# ior7f701057 register map
Registers are 8-bit, access not given, no defined reset value unless marked. A register's access mark holds for its fields unless they carry their own. Addresses are absolute; registers are grouped by the start of their names; [hi:lo] are bit positions; {n}, {i} and the like mark numbered series.

## SFR (part 1 of 3)
0xFFA00000 FLMDCNT 32-bit
0xFFA00004 FLMDPCMD 32-bit wo
0xFFA00008 FLMDPS 32-bit ro
{0xFFA08000+4i} SELFID{i} 32-bit (i=0..3)
0xFFA08010 SELFIDST 32-bit ro
0xFFA10000 FACIFPMON ro
0xFFA10010 FACIFASTAT
0xFFA10014 FACIFAEINT
0xFFA10020 FACIFAREASELC 16-bit
0xFFA10030 FACIFSADDR 32-bit
0xFFA10034 FACIFEADDR 32-bit
0xFFA10054 FACIFCURAME 16-bit
0xFFA10080 FACIFSTATR 32-bit ro
0xFFA10084 FACIFENTRYR 16-bit
0xFFA10088 FACIFPROTR 16-bit
0xFFA1008C FACIFSUINITR 16-bit
0xFFA10090 FACIFLKSTAT ro
0xFFA10094 FACIFRFSTEADR 32-bit ro
0xFFA10098 FACIFRTSTAT ro
0xFFA100A0 FACIFCMDR 16-bit ro
0xFFA100C0 FACIFPESTAT 16-bit ro
0xFFA100D0 FACIFBCCNT
0xFFA100D4 FACIFBCSTAT ro
0xFFA100D8 FACIFPSADDR 32-bit ro
0xFFA100E0 FACIFCPSR 16-bit
0xFFA100E4 FACIFPCKAR 16-bit
0xFFA10100 FACIFECCEMON 16-bit ro
0xFFA10104 FACIFECCTMD 16-bit
0xFFA10108 FACIFDMYECC 16-bit
0xFFBC0700 PFSSBWCBUFEN
{0xFFBC1000+4i} SLPWGA{i} 32-bit (i=0..2)
0xFFBC2000 SCTLR 32-bit
0xFFBC2004 EVFR 32-bit
0xFFBC2008 DPSELR0 32-bit
0xFFBC200C DPSELRM 32-bit
0xFFBC200C DPSELRML 16-bit
{0xFFBC200B+i} DPSELR{i} (i=1..7)
0xFFBC200E DPSELRMH 16-bit
0xFFBC2010 DPSELRH 32-bit
0xFFBC2010 DPSELRHL 16-bit
0xFFBC2012 DPSELRHH 16-bit
0xFFBC2014 DPDSR0 32-bit
0xFFBC2018 DPDSRM 32-bit
0xFFBC2018 DPDSRML 16-bit
{0xFFBC2017+i} DPDSR{i} (i=1..7)
0xFFBC201A DPDSRMH 16-bit
0xFFBC201C DPDSRH 32-bit
0xFFBC201C DPDSRHL 16-bit
0xFFBC201E DPDSRHH 16-bit
0xFFBC2020 DPDIMR0 32-bit ro
{0xFFBC2020+4i} DPDIMR{i} ro (i=1..7)
0xFFBC2040 CNTVAL 16-bit
0xFFBC2044 SOSTR ro
{0xFFC10000+4i} P{i} 16-bit (i=0..2)
{0xFFC10000+4i} P{i} 16-bit (i=8..12)
0xFFC10048 P18 16-bit
0xFFC10050 P20 16-bit
0xFFC100C8 AP0 16-bit
0xFFC100CC AP1 16-bit
{0xFFC10100+4i} PSR{i} 32-bit (i=0..2)
{0xFFC10100+4i} PSR{i} 32-bit (i=8..12)
0xFFC10148 PSR18 32-bit
0xFFC10150 PSR20 32-bit
0xFFC101C8 APSR0 32-bit
0xFFC101CC APSR1 32-bit
{0xFFC10200+4i} PPR{i} 16-bit ro (i=0..2)
{0xFFC10200+4i} PPR{i} 16-bit ro (i=8..12)
0xFFC10248 PPR18 16-bit ro
0xFFC10250 PPR20 16-bit ro
0xFFC102C8 APPR0 16-bit ro
0xFFC102CC APPR1 16-bit ro
0xFFC102F0 IPPR0 16-bit ro
{0xFFC10300+4i} PM{i} 16-bit (i=0..2)
{0xFFC10300+4i} PM{i} 16-bit (i=8..12)
0xFFC10348 PM18 16-bit
0xFFC10350 PM20 16-bit
0xFFC103C8 APM0 16-bit
0xFFC103CC APM1 16-bit
{0xFFC10400+4i} PMC{i} 16-bit (i=0..2)
{0xFFC10400+4i} PMC{i} 16-bit (i=8..12)
0xFFC10448 PMC18 16-bit
0xFFC10450 PMC20 16-bit
0xFFC10500 PFC0 16-bit
0xFFC10504 PFC1 16-bit
{0xFFC10500+4i} PFC{i} 16-bit (i=8..12)
0xFFC10548 PFC18 16-bit
0xFFC10550 PFC20 16-bit
0xFFC10600 PFCE0 16-bit
{0xFFC10600+4i} PFCE{i} 16-bit (i=8..12)
{0xFFC10700+4i} PNOT{i} 16-bit wo (i=0..2)
{0xFFC10700+4i} PNOT{i} 16-bit wo (i=8..12)
0xFFC10748 PNOT18 16-bit wo
0xFFC10750 PNOT20 16-bit wo
0xFFC107C8 APNOT0 16-bit wo
0xFFC107CC APNOT1 16-bit wo
{0xFFC10800+4i} PMSR{i} 32-bit (i=0..2)
{0xFFC10800+4i} PMSR{i} 32-bit (i=8..12)
0xFFC10848 PMSR18 32-bit
0xFFC10850 PMSR20 32-bit
0xFFC108C8 APMSR0 32-bit
0xFFC108CC APMSR1 32-bit
{0xFFC10900+4i} PMCSR{i} 32-bit (i=0..2)
{0xFFC10900+4i} PMCSR{i} 32-bit (i=8..12)
0xFFC10948 PMCSR18 32-bit
0xFFC10950 PMCSR20 32-bit
0xFFC10A00 PFCAE0 16-bit
0xFFC10A28 PFCAE10 16-bit
0xFFC10A2C PFCAE11 16-bit
{0xFFC14000+4i} PIBC{i} 16-bit (i=0..2)
{0xFFC14000+4i} PIBC{i} 16-bit (i=8..12)
0xFFC14048 PIBC18 16-bit
0xFFC14050 PIBC20 16-bit
0xFFC140C8 APIBC0 16-bit
0xFFC140CC APIBC1 16-bit
0xFFC140F0 IPIBC0 16-bit
{0xFFC14100+4i} PBDC{i} 16-bit (i=0..2)
{0xFFC14100+4i} PBDC{i} 16-bit (i=8..12)
0xFFC14148 PBDC18 16-bit
0xFFC14150 PBDC20 16-bit
0xFFC141C8 APBDC0 16-bit
0xFFC141CC APBDC1 16-bit
0xFFC14200 PIPC0 16-bit
0xFFC14228 PIPC10 16-bit
0xFFC1422C PIPC11 16-bit
{0xFFC14300+4i} PU{i} 16-bit (i=0..2)
{0xFFC14300+4i} PU{i} 16-bit (i=8..12)
0xFFC14348 PU18 16-bit
0xFFC14350 PU20 16-bit
0xFFC14400 PD0 16-bit
{0xFFC14400+4i} PD{i} 16-bit (i=8..11)
{0xFFC14500+4i} PODC{i} 32-bit (i=0..2)
{0xFFC14500+4i} PODC{i} 32-bit (i=8..12)
0xFFC14548 PODC18 32-bit
0xFFC14550 PODC20 32-bit
0xFFC14600 PDSC0 32-bit
{0xFFC14600+4i} PDSC{i} 32-bit (i=10..12)
{0xFFC14700+4i} PIS{i} 16-bit (i=0..2)
{0xFFC14700+4i} PIS{i} 16-bit (i=10..12)
0xFFC14750 PIS20 16-bit
{0xFFC14B00+4i} PPROTS{i} 32-bit ro (i=0..2)
{0xFFC14B00+4i} PPROTS{i} 32-bit ro (i=8..12)
0xFFC14B48 PPROTS18 32-bit ro
0xFFC14B50 PPROTS20 32-bit ro
{0xFFC14C00+4i} PPCMD{i} 32-bit wo (i=0..2)
{0xFFC14C00+4i} PPCMD{i} 32-bit wo (i=8..12)
0xFFC14C48 PPCMD18 32-bit wo
0xFFC14C50 PPCMD20 32-bit wo
0xFFC20000 JP0
0xFFC20010 JPSR0 32-bit
0xFFC20020 JPPR0 ro
0xFFC20030 JPM0
0xFFC20040 JPMC0
0xFFC20050 JPFC0
0xFFC20070 JPNOT0 wo
0xFFC20080 JPMSR0 32-bit
0xFFC20090 JPMCSR0 32-bit
0xFFC20400 JPIBC0
0xFFC20410 JPBDC0
0xFFC20430 JPU0
0xFFC20440 JPD0
0xFFC20450 JPODC0 32-bit
0xFFC204A0 JPISA0
0xFFC204B0 JPPROTS0 32-bit ro
0xFFC204C0 JPPCMD0 32-bit wo
0xFFC30000 DNFATAUD0ICTL
0xFFC30004 DNFATAUD0IEN 16-bit
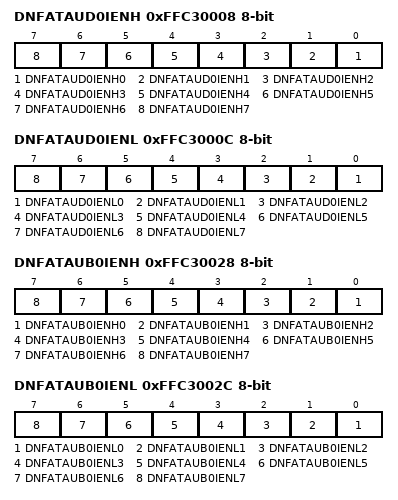
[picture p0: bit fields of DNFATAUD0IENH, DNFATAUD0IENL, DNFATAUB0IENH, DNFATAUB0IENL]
0xFFC30008 DNFATAUD0IENH
  [n] DNFATAUD0IENH{n} (n=0..7)
0xFFC3000C DNFATAUD0IENL
  [n] DNFATAUD0IENL{n} (n=0..7)
0xFFC30020 DNFATAUB0ICTL
0xFFC30024 DNFATAUB0IEN 16-bit
0xFFC30028 DNFATAUB0IENH
  [n] DNFATAUB0IENH{n} (n=0..7)
0xFFC3002C DNFATAUB0IENL
  [n] DNFATAUB0IENL{n} (n=0..7)
0xFFC30040 DNFATAUB1ICTL
0xFFC30044 DNFATAUB1IEN 16-bit
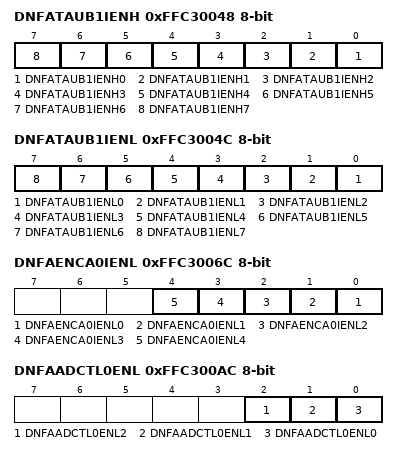
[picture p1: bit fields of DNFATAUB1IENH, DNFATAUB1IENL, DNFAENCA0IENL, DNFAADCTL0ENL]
0xFFC30048 DNFATAUB1IENH
  [n] DNFATAUB1IENH{n} (n=0..7)
0xFFC3004C DNFATAUB1IENL
  [n] DNFATAUB1IENL{n} (n=0..7)
0xFFC30060 DNFAENCA0ICTL
0xFFC30064 DNFAENCA0IEN 16-bit
0xFFC3006C DNFAENCA0IENL
  [n] DNFAENCA0IENL{n} (n=0..4)
0xFFC300A0 DNFAADCTL0CTL
0xFFC300A4 DNFAADCTL0EN 16-bit
0xFFC300AC DNFAADCTL0ENL
  [2] DNFAADCTL0ENL2, [1] DNFAADCTL0ENL1, [0] DNFAADCTL0ENL0
0xFFC300C0 DNFAADCTL1CTL
0xFFC300C4 DNFAADCTL1EN 16-bit
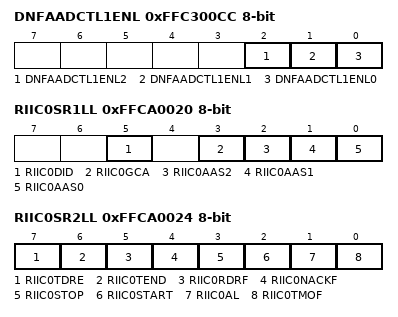
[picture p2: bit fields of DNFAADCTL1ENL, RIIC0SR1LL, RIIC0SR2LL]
0xFFC300CC DNFAADCTL1ENL
  [2] DNFAADCTL1ENL2, [1] DNFAADCTL1ENL1, [0] DNFAADCTL1ENL0
0xFFC59008 CCIBFCUFAREA
0xFFC5A010 EEPRDCYCL
0xFFC62000 CFECCCTL 16-bit
0xFFC62004 CFFSTERSTR 32-bit ro
0xFFC62024 CFFSTSTC wo
0xFFC62028 CFOVFSTR ro
0xFFC6202C CFOVFSTC wo
0xFFC62030 CFERRINT
0xFFC62034 CFFSTEADR 32-bit ro
0xFFC62054 CFTSTCTL 16-bit
0xFFC63000 LRECCCTL 16-bit
0xFFC63004 LRFSTERSTR 32-bit ro
0xFFC63024 LRSTCLR wo
0xFFC63028 LROVFSTR ro
0xFFC6302C LROVFSTC wo
0xFFC63030 LRFSTEADR0 32-bit ro
0xFFC630B0 LRERRINT
0xFFC630B4 LRTSTCTL 16-bit
0xFFC630B8 LRTDATBF0 32-bit ro
0xFFC66000 DFECCCTL 16-bit
0xFFC66004 DFERSTR 32-bit ro
0xFFC66008 DFERSTC wo
0xFFC66014 DFERRINT
0xFFC6601C DFTSTCTL 16-bit
{0xFFC70000+0x10*i} ECCCSIH{i}CTL 16-bit (i=0..3)
{0xFFC70004+0x10*i} ECCCSIH{i}TMC 16-bit (i=0..3)
{0xFFC70008+0x10*i} ECCCSIH{i}TRC 32-bit (i=0..3)
{0xFFC70008+0x10*i} ECCCSIH{i}ERDB (i=0..3)
{0xFFC70009+0x10*i} ECCCSIH{i}ECRD ro (i=0..3)
{0xFFC7000A+0x10*i} ECCCSIH{i}HORD ro (i=0..3)
{0xFFC7000B+0x10*i} ECCCSIH{i}SYND ro (i=0..3)
{0xFFC7000C+0x10*i} ECCCSIH{i}TED 32-bit (i=0..3)
0xFFC71000 ECCRCAN0CTL 16-bit
0xFFC71004 ECCRCAN0TMC 16-bit
0xFFC71008 ECCRCAN0TRC 32-bit
0xFFC71008 ECCRCAN0ERDB
0xFFC71009 ECCRCAN0ECRD ro
0xFFC7100A ECCRCAN0HORD ro
0xFFC7100B ECCRCAN0SYND ro
0xFFC7100C ECCRCAN0TED 32-bit
0xFFCA0000 RIIC0CR1 32-bit
0xFFCA0000 RIIC0CR1L 16-bit
0xFFCA0000 RIIC0CR1LL
0xFFCA0001 RIIC0CR1LH
0xFFCA0002 RIIC0CR1H 16-bit
0xFFCA0002 RIIC0CR1HL
0xFFCA0003 RIIC0CR1HH
0xFFCA0004 RIIC0CR2 32-bit
0xFFCA0004 RIIC0CR2L 16-bit
0xFFCA0004 RIIC0CR2LL
0xFFCA0005 RIIC0CR2LH
0xFFCA0006 RIIC0CR2H 16-bit
0xFFCA0006 RIIC0CR2HL
0xFFCA0007 RIIC0CR2HH
{0xFFCA0004+4i} RIIC0MR{i} 32-bit (i=1..3)
{0xFFCA0004+4i} RIIC0MR{i}L 16-bit (i=1..3)
{0xFFCA0004+4i} RIIC0MR{i}LL (i=1..3)
{0xFFCA0005+4i} RIIC0MR{i}LH (i=1..3)
{0xFFCA0006+4i} RIIC0MR{i}H 16-bit (i=1..3)
{0xFFCA0006+4i} RIIC0MR{i}HL (i=1..3)
{0xFFCA0007+4i} RIIC0MR{i}HH (i=1..3)
0xFFCA0014 RIIC0FER 32-bit
0xFFCA0014 RIIC0FERL 16-bit
0xFFCA0014 RIIC0FERLL
0xFFCA0015 RIIC0FERLH
0xFFCA0016 RIIC0FERH 16-bit
0xFFCA0016 RIIC0FERHL
0xFFCA0017 RIIC0FERHH
0xFFCA0018 RIIC0SER 32-bit
0xFFCA0018 RIIC0SERL 16-bit
0xFFCA0018 RIIC0SERLL
0xFFCA0019 RIIC0SERLH
0xFFCA001A RIIC0SERH 16-bit
0xFFCA001A RIIC0SERHL
0xFFCA001B RIIC0SERHH
0xFFCA001C RIIC0IER 32-bit
0xFFCA001C RIIC0IERL 16-bit
0xFFCA001C RIIC0IERLL
0xFFCA001D RIIC0IERLH
0xFFCA001E RIIC0IERH 16-bit
0xFFCA001E RIIC0IERHL
0xFFCA001F RIIC0IERHH
0xFFCA0020 RIIC0SR1 32-bit
0xFFCA0020 RIIC0SR1L 16-bit
0xFFCA0020 RIIC0SR1LL
  [5] RIIC0DID, [3] RIIC0GCA, [2] RIIC0AAS2, [1] RIIC0AAS1, [0] RIIC0AAS0
0xFFCA0021 RIIC0SR1LH
0xFFCA0022 RIIC0SR1H 16-bit
0xFFCA0022 RIIC0SR1HL
0xFFCA0023 RIIC0SR1HH
0xFFCA0024 RIIC0SR2 32-bit
0xFFCA0024 RIIC0SR2L 16-bit
0xFFCA0024 RIIC0SR2LL
  [7] RIIC0TDRE ro, [6] RIIC0TEND, [5] RIIC0RDRF, [4] RIIC0NACKF, [3] RIIC0STOP, [2] RIIC0START, [1] RIIC0AL, [0] RIIC0TMOF
0xFFCA0025 RIIC0SR2LH
0xFFCA0026 RIIC0SR2H 16-bit
0xFFCA0026 RIIC0SR2HL
0xFFCA0027 RIIC0SR2HH
{0xFFCA0028+4i} RIIC0SAR{i} 32-bit (i=0..2)
{0xFFCA0028+4i} RIIC0SAR{i}L 16-bit (i=0..2)
{0xFFCA0028+4i} RIIC0SAR{i}LL (i=0..2)
{0xFFCA0029+4i} RIIC0SAR{i}LH (i=0..2)
{0xFFCA002A+4i} RIIC0SAR{i}H 16-bit (i=0..2)
{0xFFCA002A+4i} RIIC0SAR{i}HL (i=0..2)
{0xFFCA002B+4i} RIIC0SAR{i}HH (i=0..2)
0xFFCA0034 RIIC0BRL 32-bit
0xFFCA0034 RIIC0BRLL 16-bit
0xFFCA0034 RIIC0BRLLL
0xFFCA0035 RIIC0BRLLH
0xFFCA0036 RIIC0BRLH 16-bit
0xFFCA0036 RIIC0BRLHL
0xFFCA0037 RIIC0BRLHH
0xFFCA0038 RIIC0BRH 32-bit
0xFFCA0038 RIIC0BRHL 16-bit
0xFFCA0038 RIIC0BRHLL
0xFFCA0039 RIIC0BRHLH
0xFFCA003A RIIC0BRHH 16-bit
0xFFCA003A RIIC0BRHHL
0xFFCA003B RIIC0BRHHH
0xFFCA003C RIIC0DRT 32-bit
0xFFCA003C RIIC0DRTL 16-bit
0xFFCA003C RIIC0DRTLL
0xFFCA003D RIIC0DRTLH
0xFFCA003E RIIC0DRTH 16-bit
0xFFCA003E RIIC0DRTHL
0xFFCA003F RIIC0DRTHH
0xFFCA0040 RIIC0DRR 32-bit ro
0xFFCA0040 RIIC0DRRL 16-bit ro
0xFFCA0040 RIIC0DRRLL ro
0xFFCA0041 RIIC0DRRLH ro
0xFFCA0042 RIIC0DRRH 16-bit ro
0xFFCA0042 RIIC0DRRHL ro
0xFFCA0043 RIIC0DRRHH ro
{0xFFCD00CC+4i} SCDSPRDNAME{i} 32-bit (i=1..3)
0xFFCE0001 RLN240GLWBR
0xFFCE0002 RLN240GLBRP0
0xFFCE0003 RLN240GLBRP1
0xFFCE0004 RLN240GLSTC
{0xFFCCD408+0x20*i} RLN{i}L{i-2400}MD (i=2400..2403)
{0xFFCCD409+0x20*i} RLN{i}L{i-2400}BFC (i=2400..2403)
{0xFFCCD40A+0x20*i} RLN{i}L{i-2400}SC (i=2400..2403)
{0xFFCCD40B+0x20*i} RLN{i}L{i-2400}WUP (i=2400..2403)
{0xFFCCD40C+0x20*i} RLN{i}L{i-2400}IE (i=2400..2403)
{0xFFCCD40D+0x20*i} RLN{i}L{i-2400}EDE (i=2400..2403)
{0xFFCCD40E+0x20*i} RLN{i}L{i-2400}CUC (i=2400..2403)
{0xFFCCD410+0x20*i} RLN{i}L{i-2400}TRC (i=2400..2403)
{0xFFCCD411+0x20*i} RLN{i}L{i-2400}MST ro (i=2400..2403)
{0xFFCCD412+0x20*i} RLN{i}L{i-2400}ST (i=2400..2403)
{0xFFCCD413+0x20*i} RLN{i}L{i-2400}EST (i=2400..2403)
{0xFFCCD414+0x20*i} RLN{i}L{i-2400}DFC (i=2400..2403)
{0xFFCCD415+0x20*i} RLN{i}L{i-2400}IDB (i=2400..2403)
{0xFFCCD416+0x20*i} RLN{i}L{i-2400}CBR (i=2400..2403)
{0xFFCE0017+i} RLN2400L0DBR{i} (i=1..8)
{0xFFCE0037+i} RLN2401L1DBR{i} (i=1..8)
{0xFFCE0057+i} RLN2402L2DBR{i} (i=1..8)
{0xFFCE0077+i} RLN2403L3DBR{i} (i=1..8)
0xFFCE0081 RLN241GLWBR
0xFFCE0082 RLN241GLBRP0
0xFFCE0083 RLN241GLBRP1
0xFFCE0084 RLN241GLSTC
{0xFFCCD2C8+0x20*i} RLN{i}L{i-2414}MD (i=2414..2417)
{0xFFCCD2C9+0x20*i} RLN{i}L{i-2414}BFC (i=2414..2417)
{0xFFCCD2CA+0x20*i} RLN{i}L{i-2414}SC (i=2414..2417)
{0xFFCCD2CB+0x20*i} RLN{i}L{i-2414}WUP (i=2414..2417)
{0xFFCCD2CC+0x20*i} RLN{i}L{i-2414}IE (i=2414..2417)
{0xFFCCD2CD+0x20*i} RLN{i}L{i-2414}EDE (i=2414..2417)
{0xFFCCD2CE+0x20*i} RLN{i}L{i-2414}CUC (i=2414..2417)
{0xFFCCD2D0+0x20*i} RLN{i}L{i-2414}TRC (i=2414..2417)
{0xFFCCD2D1+0x20*i} RLN{i}L{i-2414}MST ro (i=2414..2417)
{0xFFCCD2D2+0x20*i} RLN{i}L{i-2414}ST (i=2414..2417)
{0xFFCCD2D3+0x20*i} RLN{i}L{i-2414}EST (i=2414..2417)
{0xFFCCD2D4+0x20*i} RLN{i}L{i-2414}DFC (i=2414..2417)
{0xFFCCD2D5+0x20*i} RLN{i}L{i-2414}IDB (i=2414..2417)
{0xFFCCD2D6+0x20*i} RLN{i}L{i-2414}CBR (i=2414..2417)
{0xFFCE0097+i} RLN2414L0DBR{i} (i=1..8)
{0xFFCE00B7+i} RLN2415L1DBR{i} (i=1..8)
{0xFFCE00D7+i} RLN2416L2DBR{i} (i=1..8)
{0xFFCE00F7+i} RLN2417L3DBR{i} (i=1..8)
0xFFCE0101 RLN210GLWBR
0xFFCE0102 RLN210GLBRP0
0xFFCE0103 RLN210GLBRP1
0xFFCE0104 RLN210GLSTC
0xFFCE0108 RLN2108L0MD
0xFFCE0109 RLN2108L0BFC
0xFFCE010A RLN2108L0SC
0xFFCE010B RLN2108L0WUP
0xFFCE010C RLN2108L0IE
0xFFCE010D RLN2108L0EDE
0xFFCE010E RLN2108L0CUC
0xFFCE0110 RLN2108L0TRC
0xFFCE0111 RLN2108L0MST ro
0xFFCE0112 RLN2108L0ST
0xFFCE0113 RLN2108L0EST
0xFFCE0114 RLN2108L0DFC
0xFFCE0115 RLN2108L0IDB
0xFFCE0116 RLN2108L0CBR
{0xFFCE0117+i} RLN2108L0DBR{i} (i=1..8)
0xFFCE0121 RLN211GLWBR
0xFFCE0122 RLN211GLBRP0
0xFFCE0123 RLN211GLBRP1
0xFFCE0124 RLN211GLSTC
0xFFCE0128 RLN2119L0MD
0xFFCE0129 RLN2119L0BFC
0xFFCE012A RLN2119L0SC
0xFFCE012B RLN2119L0WUP
0xFFCE012C RLN2119L0IE
0xFFCE012D RLN2119L0EDE
0xFFCE012E RLN2119L0CUC
0xFFCE0130 RLN2119L0TRC
0xFFCE0131 RLN2119L0MST ro
0xFFCE0132 RLN2119L0ST
0xFFCE0133 RLN2119L0EST
0xFFCE0134 RLN2119L0DFC
0xFFCE0135 RLN2119L0IDB
0xFFCE0136 RLN2119L0CBR
{0xFFCE0137+i} RLN2119L0DBR{i} (i=1..8)
{0xFFCEF881+0x40*i} RLN{i}LWBR (i=30..35)
{0xFFCEF882+0x40*i} RLN{i}LBRP01 16-bit (i=30..35)
{0xFFCEF882+0x40*i} RLN{i}LBRP0 (i=30..35)
{0xFFCEF883+0x40*i} RLN{i}LBRP1 (i=30..35)
{0xFFCEF884+0x40*i} RLN{i}LSTC (i=30..35)
{0xFFCEF888+0x40*i} RLN{i}LMD (i=30..35)
{0xFFCEF889+0x40*i} RLN{i}LBFC (i=30..35)
{0xFFCEF88A+0x40*i} RLN{i}LSC (i=30..35)
{0xFFCEF88B+0x40*i} RLN{i}LWUP (i=30..35)
{0xFFCEF88C+0x40*i} RLN{i}LIE (i=30..35)
{0xFFCEF88D+0x40*i} RLN{i}LEDE (i=30..35)
{0xFFCEF88E+0x40*i} RLN{i}LCUC (i=30..35)
{0xFFCEF890+0x40*i} RLN{i}LTRC (i=30..35)
{0xFFCEF891+0x40*i} RLN{i}LMST ro (i=30..35)
{0xFFCEF892+0x40*i} RLN{i}LST (i=30..35)
{0xFFCEF893+0x40*i} RLN{i}LEST (i=30..35)
{0xFFCEF894+0x40*i} RLN{i}LDFC (i=30..35)
{0xFFCEF895+0x40*i} RLN{i}LIDB (i=30..35)
{0xFFCEF896+0x40*i} RLN{i}LCBR (i=30..35)
{0xFFCEF897+0x40*i} RLN{i}LUDB0 (i=30..35)
{0xFFCF0017+i} RLN30LDBR{i} (i=1..8)
{0xFFCEF8A0+0x40*i} RLN{i}LUOER (i=30..35)
{0xFFCEF8A1+0x40*i} RLN{i}LUOR1 (i=30..35)
{0xFFCEF8A4+0x40*i} RLN{i}LUTDR 16-bit (i=30..35)
{0xFFCEF8A4+0x40*i} RLN{i}LUTDRL (i=30..35)
{0xFFCEF8A5+0x40*i} RLN{i}LUTDRH (i=30..35)
{0xFFCEF8A6+0x40*i} RLN{i}LURDR 16-bit ro (i=30..35)
{0xFFCEF8A6+0x40*i} RLN{i}LURDRL ro (i=30..35)
{0xFFCEF8A7+0x40*i} RLN{i}LURDRH ro (i=30..35)
{0xFFCEF8A8+0x40*i} RLN{i}LUWTDR 16-bit (i=30..35)
{0xFFCEF8A8+0x40*i} RLN{i}LUWTDRL (i=30..35)
{0xFFCEF8A9+0x40*i} RLN{i}LUWTDRH (i=30..35)
{0xFFCF0057+i} RLN31LDBR{i} (i=1..8)
{0xFFCF0097+i} RLN32LDBR{i} (i=1..8)
{0xFFCF00D7+i} RLN33LDBR{i} (i=1..8)
{0xFFCF0117+i} RLN34LDBR{i} (i=1..8)
{0xFFCF0157+i} RLN35LDBR{i} (i=1..8)
{0xFFD00000+0x10*i} RSCAN0C{i}CFG 32-bit (i=0..5)
{0xFFD00000+0x10*i} RSCAN0C{i}CFGL 16-bit (i=0..5)
{0xFFD00000+0x10*i} RSCAN0C{i}CFGLL (i=0..5)
{0xFFD00001+0x10*i} RSCAN0C{i}CFGLH (i=0..5)
{0xFFD00002+0x10*i} RSCAN0C{i}CFGH 16-bit (i=0..5)
{0xFFD00002+0x10*i} RSCAN0C{i}CFGHL (i=0..5)
{0xFFD00003+0x10*i} RSCAN0C{i}CFGHH (i=0..5)
{0xFFD00004+0x10*i} RSCAN0C{i}CTR 32-bit (i=0..5)
{0xFFD00004+0x10*i} RSCAN0C{i}CTRL 16-bit (i=0..5)
{0xFFD00004+0x10*i} RSCAN0C{i}CTRLL (i=0..5)
{0xFFD00005+0x10*i} RSCAN0C{i}CTRLH (i=0..5)
{0xFFD00006+0x10*i} RSCAN0C{i}CTRH 16-bit (i=0..5)
{0xFFD00006+0x10*i} RSCAN0C{i}CTRHL (i=0..5)
{0xFFD00007+0x10*i} RSCAN0C{i}CTRHH (i=0..5)
{0xFFD00008+0x10*i} RSCAN0C{i}STS 32-bit ro (i=0..5)
{0xFFD00008+0x10*i} RSCAN0C{i}STSL 16-bit ro (i=0..5)
{0xFFD00008+0x10*i} RSCAN0C{i}STSLL ro (i=0..5)
{0xFFD0000A+0x10*i} RSCAN0C{i}STSH 16-bit ro (i=0..5)
{0xFFD0000A+0x10*i} RSCAN0C{i}STSHL ro (i=0..5)
{0xFFD0000B+0x10*i} RSCAN0C{i}STSHH ro (i=0..5)
{0xFFD0000C+0x10*i} RSCAN0C{i}ERFL 32-bit (i=0..5)
{0xFFD0000C+0x10*i} RSCAN0C{i}ERFLL 16-bit (i=0..5)
{0xFFD0000C+0x10*i} RSCAN0C{i}ERFLLL (i=0..5)
{0xFFD0000D+0x10*i} RSCAN0C{i}ERFLLH (i=0..5)
{0xFFD0000E+0x10*i} RSCAN0C{i}ERFLH 16-bit ro (i=0..5)
{0xFFD0000E+0x10*i} RSCAN0C{i}ERFLHL ro (i=0..5)
{0xFFD0000F+0x10*i} RSCAN0C{i}ERFLHH ro (i=0..5)
0xFFD00084 RSCAN0GCFG 32-bit
0xFFD00084 RSCAN0GCFGL 16-bit
0xFFD00084 RSCAN0GCFGLL
0xFFD00085 RSCAN0GCFGLH
0xFFD00086 RSCAN0GCFGH 16-bit
0xFFD00086 RSCAN0GCFGHL
0xFFD00087 RSCAN0GCFGHH
0xFFD00088 RSCAN0GCTR 32-bit
0xFFD00088 RSCAN0GCTRL 16-bit
0xFFD00088 RSCAN0GCTRLL
0xFFD00089 RSCAN0GCTRLH
0xFFD0008A RSCAN0GCTRH 16-bit
0xFFD0008A RSCAN0GCTRHL
0xFFD0008C RSCAN0GSTS 32-bit ro
0xFFD0008C RSCAN0GSTSL 16-bit ro
0xFFD0008C RSCAN0GSTSLL ro
0xFFD00090 RSCAN0GERFL 32-bit
0xFFD00090 RSCAN0GERFLL 16-bit
0xFFD00090 RSCAN0GERFLLL
0xFFD00094 RSCAN0GTSC 32-bit ro
0xFFD00094 RSCAN0GTSCL 16-bit ro
0xFFD00098 RSCAN0GAFLECTR 32-bit
0xFFD00098 RSCAN0GAFLECTRL 16-bit
0xFFD00098 RSCAN0GAFLECTRLL
0xFFD00099 RSCAN0GAFLECTRLH
0xFFD0009C RSCAN0GAFLCFG0 32-bit
0xFFD0009C RSCAN0GAFLCFG0L 16-bit
0xFFD0009C RSCAN0GAFLCFG0LL
0xFFD0009D RSCAN0GAFLCFG0LH
0xFFD0009E RSCAN0GAFLCFG0H 16-bit
0xFFD0009E RSCAN0GAFLCFG0HL
0xFFD0009F RSCAN0GAFLCFG0HH
0xFFD000A0 RSCAN0GAFLCFG1 32-bit
0xFFD000A2 RSCAN0GAFLCFG1H 16-bit
0xFFD000A2 RSCAN0GAFLCFG1HL
0xFFD000A3 RSCAN0GAFLCFG1HH
0xFFD000A4 RSCAN0RMNB 32-bit
0xFFD000A4 RSCAN0RMNBL 16-bit
0xFFD000A4 RSCAN0RMNBLL
{0xFFD000A8+4i} RSCAN0RMND{i} 32-bit (i=0..2)
{0xFFD000A8+4i} RSCAN0RMND{i}L 16-bit (i=0..2)
{0xFFD000A8+4i} RSCAN0RMND{i}LL (i=0..2)
{0xFFD000A9+4i} RSCAN0RMND{i}LH (i=0..2)
{0xFFD000AA+4i} RSCAN0RMND{i}H 16-bit (i=0..2)
{0xFFD000AA+4i} RSCAN0RMND{i}HL (i=0..2)
{0xFFD000AB+4i} RSCAN0RMND{i}HH (i=0..2)
{0xFFD000B8+4i} RSCAN0RFCC{i} 32-bit (i=0..7)
{0xFFD000B8+4i} RSCAN0RFCC{i}L 16-bit (i=0..7)
{0xFFD000B8+4i} RSCAN0RFCC{i}LL (i=0..7)
{0xFFD000B9+4i} RSCAN0RFCC{i}LH (i=0..7)
{0xFFD000D8+4i} RSCAN0RFSTS{i} 32-bit (i=0..7)
{0xFFD000D8+4i} RSCAN0RFSTS{i}L 16-bit (i=0..7)
{0xFFD000D8+4i} RSCAN0RFSTS{i}LL (i=0..7)
{0xFFD000D9+4i} RSCAN0RFSTS{i}LH ro (i=0..7)
{0xFFD000F8+4i} RSCAN0RFPCTR{i} 32-bit wo (i=0..7)
{0xFFD000F8+4i} RSCAN0RFPCTR{i}L 16-bit wo (i=0..7)
{0xFFD000F8+4i} RSCAN0RFPCTR{i}LL wo (i=0..7)
{0xFFD00118+4i} RSCAN0CFCC{i} 32-bit (i=0..17)
{0xFFD00118+4i} RSCAN0CFCC{i}L 16-bit (i=0..17)
{0xFFD00118+4i} RSCAN0CFCC{i}LL (i=0..17)
{0xFFD00119+4i} RSCAN0CFCC{i}LH (i=0..17)
{0xFFD0011A+4i} RSCAN0CFCC{i}H 16-bit (i=0..17)
{0xFFD0011A+4i} RSCAN0CFCC{i}HL (i=0..17)
{0xFFD0011B+4i} RSCAN0CFCC{i}HH (i=0..17)
{0xFFD00178+4i} RSCAN0CFSTS{i} 32-bit (i=0..17)
{0xFFD00178+4i} RSCAN0CFSTS{i}L 16-bit (i=0..17)
{0xFFD00178+4i} RSCAN0CFSTS{i}LL (i=0..17)
{0xFFD00179+4i} RSCAN0CFSTS{i}LH ro (i=0..17)
{0xFFD001D8+4i} RSCAN0CFPCTR{i} 32-bit wo (i=0..17)
{0xFFD001D8+4i} RSCAN0CFPCTR{i}L 16-bit wo (i=0..17)
{0xFFD001D8+4i} RSCAN0CFPCTR{i}LL wo (i=0..17)
0xFFD00238 RSCAN0FESTS 32-bit ro
0xFFD00238 RSCAN0FESTSL 16-bit ro
0xFFD00238 RSCAN0FESTSLL ro
0xFFD00239 RSCAN0FESTSLH ro
0xFFD0023A RSCAN0FESTSH 16-bit ro
0xFFD0023A RSCAN0FESTSHL ro
0xFFD0023B RSCAN0FESTSHH ro
0xFFD0023C RSCAN0FFSTS 32-bit ro
0xFFD0023C RSCAN0FFSTSL 16-bit ro
0xFFD0023C RSCAN0FFSTSLL ro
0xFFD0023D RSCAN0FFSTSLH ro
0xFFD0023E RSCAN0FFSTSH 16-bit ro
0xFFD0023E RSCAN0FFSTSHL ro
0xFFD0023F RSCAN0FFSTSHH ro
0xFFD00240 RSCAN0FMSTS 32-bit ro
0xFFD00240 RSCAN0FMSTSL 16-bit ro
0xFFD00240 RSCAN0FMSTSLL ro
0xFFD00241 RSCAN0FMSTSLH ro
0xFFD00242 RSCAN0FMSTSH 16-bit ro
0xFFD00242 RSCAN0FMSTSHL ro
0xFFD00243 RSCAN0FMSTSHH ro
0xFFD00244 RSCAN0RFISTS 32-bit ro
0xFFD00244 RSCAN0RFISTSL 16-bit ro
0xFFD00244 RSCAN0RFISTSLL ro
0xFFD00248 RSCAN0CFRISTS 32-bit ro
0xFFD00248 RSCAN0CFRISTSL 16-bit ro
0xFFD00248 RSCAN0CFRISTSLL ro
0xFFD00249 RSCAN0CFRISTSLH ro
0xFFD0024A RSCAN0CFRISTSH 16-bit ro
0xFFD0024A RSCAN0CFRISTSHL ro
0xFFD0024C RSCAN0CFTISTS 32-bit ro
0xFFD0024C RSCAN0CFTISTSL 16-bit ro
0xFFD0024C RSCAN0CFTISTSLL ro
0xFFD0024D RSCAN0CFTISTSLH ro
0xFFD0024E RSCAN0CFTISTSH 16-bit ro
0xFFD0024E RSCAN0CFTISTSHL ro
{0xFFD00250+i} RSCAN0TMC{i} (i=0..95)
{0xFFD002D0+i} RSCAN0TMSTS{i} (i=0..95)
{0xFFD00350+4i} RSCAN0TMTRSTS{i} 32-bit ro (i=0..2)
{0xFFD00350+4i} RSCAN0TMTRSTS{i}L 16-bit ro (i=0..2)
{0xFFD00350+4i} RSCAN0TMTRSTS{i}LL ro (i=0..2)
{0xFFD00351+4i} RSCAN0TMTRSTS{i}LH ro (i=0..2)
{0xFFD00352+4i} RSCAN0TMTRSTS{i}H 16-bit ro (i=0..2)
{0xFFD00352+4i} RSCAN0TMTRSTS{i}HL ro (i=0..2)
{0xFFD00353+4i} RSCAN0TMTRSTS{i}HH ro (i=0..2)
{0xFFD00360+4i} RSCAN0TMTARSTS{i} 32-bit ro (i=0..2)
{0xFFD00360+4i} RSCAN0TMTARSTS{i}L 16-bit ro (i=0..2)
{0xFFD00360+4i} RSCAN0TMTARSTS{i}LL ro (i=0..2)
{0xFFD00361+4i} RSCAN0TMTARSTS{i}LH ro (i=0..2)
{0xFFD00362+4i} RSCAN0TMTARSTS{i}H 16-bit ro (i=0..2)
{0xFFD00362+4i} RSCAN0TMTARSTS{i}HL ro (i=0..2)
{0xFFD00363+4i} RSCAN0TMTARSTS{i}HH ro (i=0..2)
{0xFFD00370+4i} RSCAN0TMTCSTS{i} 32-bit ro (i=0..2)
{0xFFD00370+4i} RSCAN0TMTCSTS{i}L 16-bit ro (i=0..2)
{0xFFD00370+4i} RSCAN0TMTCSTS{i}LL ro (i=0..2)
{0xFFD00371+4i} RSCAN0TMTCSTS{i}LH ro (i=0..2)
{0xFFD00372+4i} RSCAN0TMTCSTS{i}H 16-bit ro (i=0..2)
{0xFFD00372+4i} RSCAN0TMTCSTS{i}HL ro (i=0..2)
{0xFFD00373+4i} RSCAN0TMTCSTS{i}HH ro (i=0..2)
{0xFFD00380+4i} RSCAN0TMTASTS{i} 32-bit ro (i=0..2)
{0xFFD00380+4i} RSCAN0TMTASTS{i}L 16-bit ro (i=0..2)
{0xFFD00380+4i} RSCAN0TMTASTS{i}LL ro (i=0..2)
{0xFFD00381+4i} RSCAN0TMTASTS{i}LH ro (i=0..2)
{0xFFD00382+4i} RSCAN0TMTASTS{i}H 16-bit ro (i=0..2)
{0xFFD00382+4i} RSCAN0TMTASTS{i}HL ro (i=0..2)
{0xFFD00383+4i} RSCAN0TMTASTS{i}HH ro (i=0..2)
{0xFFD00390+4i} RSCAN0TMIEC{i} 32-bit (i=0..2)
{0xFFD00390+4i} RSCAN0TMIEC{i}L 16-bit (i=0..2)
{0xFFD00390+4i} RSCAN0TMIEC{i}LL (i=0..2)
{0xFFD00391+4i} RSCAN0TMIEC{i}LH (i=0..2)
{0xFFD00392+4i} RSCAN0TMIEC{i}H 16-bit (i=0..2)
{0xFFD00392+4i} RSCAN0TMIEC{i}HL (i=0..2)
{0xFFD00393+4i} RSCAN0TMIEC{i}HH (i=0..2)
{0xFFD003A0+4i} RSCAN0TXQCC{i} 32-bit (i=0..5)
{0xFFD003A0+4i} RSCAN0TXQCC{i}L 16-bit (i=0..5)
{0xFFD003A0+4i} RSCAN0TXQCC{i}LL (i=0..5)
{0xFFD003A1+4i} RSCAN0TXQCC{i}LH (i=0..5)
{0xFFD003C0+4i} RSCAN0TXQSTS{i} 32-bit (i=0..5)
{0xFFD003C0+4i} RSCAN0TXQSTS{i}L 16-bit (i=0..5)
{0xFFD003C0+4i} RSCAN0TXQSTS{i}LL (i=0..5)
{0xFFD003E0+4i} RSCAN0TXQPCTR{i} 32-bit wo (i=0..5)
{0xFFD003E0+4i} RSCAN0TXQPCTR{i}L 16-bit wo (i=0..5)
{0xFFD003E0+4i} RSCAN0TXQPCTR{i}LL wo (i=0..5)
{0xFFD00400+4i} RSCAN0THLCC{i} 32-bit (i=0..5)
{0xFFD00400+4i} RSCAN0THLCC{i}L 16-bit (i=0..5)
{0xFFD00400+4i} RSCAN0THLCC{i}LL (i=0..5)
{0xFFD00401+4i} RSCAN0THLCC{i}LH (i=0..5)
{0xFFD00420+4i} RSCAN0THLSTS{i} 32-bit (i=0..5)
{0xFFD00420+4i} RSCAN0THLSTS{i}L 16-bit (i=0..5)
{0xFFD00420+4i} RSCAN0THLSTS{i}LL (i=0..5)
{0xFFD00421+4i} RSCAN0THLSTS{i}LH ro (i=0..5)
{0xFFD00440+4i} RSCAN0THLPCTR{i} 32-bit wo (i=0..5)
{0xFFD00440+4i} RSCAN0THLPCTR{i}L 16-bit wo (i=0..5)
{0xFFD00440+4i} RSCAN0THLPCTR{i}LL wo (i=0..5)
0xFFD00460 RSCAN0GTINTSTS0 32-bit ro
0xFFD00460 RSCAN0GTINTSTS0L 16-bit ro
0xFFD00460 RSCAN0GTINTSTS0LL ro
0xFFD00461 RSCAN0GTINTSTS0LH ro
0xFFD00462 RSCAN0GTINTSTS0H 16-bit ro
0xFFD00462 RSCAN0GTINTSTS0HL ro
0xFFD00463 RSCAN0GTINTSTS0HH ro
0xFFD00464 RSCAN0GTINTSTS1 32-bit ro
0xFFD00464 RSCAN0GTINTSTS1L 16-bit ro
0xFFD00464 RSCAN0GTINTSTS1LL ro
0xFFD00465 RSCAN0GTINTSTS1LH ro
0xFFD00468 RSCAN0GTSTCFG 32-bit
0xFFD00468 RSCAN0GTSTCFGL 16-bit
0xFFD00468 RSCAN0GTSTCFGLL
0xFFD0046A RSCAN0GTSTCFGH 16-bit
0xFFD0046A RSCAN0GTSTCFGHL
0xFFD0046C RSCAN0GTSTCTR 32-bit
0xFFD0046C RSCAN0GTSTCTRL 16-bit
0xFFD0046C RSCAN0GTSTCTRLL
0xFFD0047C RSCAN0GLOCKK 32-bit wo
0xFFD0047C RSCAN0GLOCKKL 16-bit wo
{0xFFD00500+0x10*i} RSCAN0GAFLID{i} 32-bit (i=0..15)
{0xFFD00500+0x10*i} RSCAN0GAFLID{i}L 16-bit (i=0..15)
{0xFFD00500+0x10*i} RSCAN0GAFLID{i}LL (i=0..15)
{0xFFD00501+0x10*i} RSCAN0GAFLID{i}LH (i=0..15)
{0xFFD00502+0x10*i} RSCAN0GAFLID{i}H 16-bit (i=0..15)
{0xFFD00502+0x10*i} RSCAN0GAFLID{i}HL (i=0..15)
{0xFFD00503+0x10*i} RSCAN0GAFLID{i}HH (i=0..15)
{0xFFD00504+0x10*i} RSCAN0GAFLM{i} 32-bit (i=0..15)
{0xFFD00504+0x10*i} RSCAN0GAFLM{i}L 16-bit (i=0..15)
{0xFFD00504+0x10*i} RSCAN0GAFLM{i}LL (i=0..15)
{0xFFD00505+0x10*i} RSCAN0GAFLM{i}LH (i=0..15)
{0xFFD00506+0x10*i} RSCAN0GAFLM{i}H 16-bit (i=0..15)
{0xFFD00506+0x10*i} RSCAN0GAFLM{i}HL (i=0..15)
{0xFFD00507+0x10*i} RSCAN0GAFLM{i}HH (i=0..15)
{0xFFD00508+0x10*i} RSCAN0GAFLP{i:02} 32-bit (i=0..9)
{0xFFD00508+0x10*i} RSCAN0GAFLP{i:02}L 16-bit (i=0..9)
{0xFFD00509+0x10*i} RSCAN0GAFLP{i:02}LH (i=0..9)
{0xFFD0050A+0x10*i} RSCAN0GAFLP{i:02}H 16-bit (i=0..9)
{0xFFD0050A+0x10*i} RSCAN0GAFLP{i:02}HL (i=0..9)
{0xFFD0050B+0x10*i} RSCAN0GAFLP{i:02}HH (i=0..9)
0xFFD0050C RSCAN0GAFLP10 32-bit
0xFFD0050C RSCAN0GAFLP10L 16-bit
{0xFFD0046C+0x10*i} RSCAN0GAFLP{i}LL (i=10..19)
0xFFD0050D RSCAN0GAFLP10LH
0xFFD0050E RSCAN0GAFLP10H 16-bit
0xFFD0050E RSCAN0GAFLP10HL
0xFFD0050F RSCAN0GAFLP10HH
0xFFD0051C RSCAN0GAFLP11 32-bit
0xFFD0051C RSCAN0GAFLP11L 16-bit
0xFFD0051D RSCAN0GAFLP11LH
0xFFD0051E RSCAN0GAFLP11H 16-bit
0xFFD0051E RSCAN0GAFLP11HL
0xFFD0051F RSCAN0GAFLP11HH
0xFFD0052C RSCAN0GAFLP12 32-bit
0xFFD0052C RSCAN0GAFLP12L 16-bit
0xFFD0052D RSCAN0GAFLP12LH
0xFFD0052E RSCAN0GAFLP12H 16-bit
0xFFD0052E RSCAN0GAFLP12HL
0xFFD0052F RSCAN0GAFLP12HH
0xFFD0053C RSCAN0GAFLP13 32-bit
0xFFD0053C RSCAN0GAFLP13L 16-bit
0xFFD0053D RSCAN0GAFLP13LH
0xFFD0053E RSCAN0GAFLP13H 16-bit
0xFFD0053E RSCAN0GAFLP13HL
0xFFD0053F RSCAN0GAFLP13HH
0xFFD0054C RSCAN0GAFLP14 32-bit
0xFFD0054C RSCAN0GAFLP14L 16-bit
0xFFD0054D RSCAN0GAFLP14LH
0xFFD0054E RSCAN0GAFLP14H 16-bit
0xFFD0054E RSCAN0GAFLP14HL
0xFFD0054F RSCAN0GAFLP14HH
0xFFD0055C RSCAN0GAFLP15 32-bit
0xFFD0055C RSCAN0GAFLP15L 16-bit
0xFFD0055D RSCAN0GAFLP15LH
0xFFD0055E RSCAN0GAFLP15H 16-bit
0xFFD0055E RSCAN0GAFLP15HL
0xFFD0055F RSCAN0GAFLP15HH
{0xFFD0046C+0x10*i} RSCAN0GAFLP{i} 32-bit (i=16..19)
{0xFFD0046C+0x10*i} RSCAN0GAFLP{i}L 16-bit (i=16..19)
{0xFFD0046D+0x10*i} RSCAN0GAFLP{i}LH (i=16..19)
{0xFFD0046E+0x10*i} RSCAN0GAFLP{i}H 16-bit (i=16..19)
{0xFFD0046E+0x10*i} RSCAN0GAFLP{i}HL (i=16..19)
{0xFFD0046F+0x10*i} RSCAN0GAFLP{i}HH (i=16..19)
0xFFD005A8 RSCAN0GAFLP010 32-bit
0xFFD005A8 RSCAN0GAFLP010L 16-bit
0xFFD005A9 RSCAN0GAFLP010LH
0xFFD005AA RSCAN0GAFLP010H 16-bit
0xFFD005AA RSCAN0GAFLP010HL
0xFFD005AB RSCAN0GAFLP010HH
{0xFFCFFECC+0x10*i} RSCAN0GAFLP{i} 32-bit (i=110..115)
{0xFFCFFECC+0x10*i} RSCAN0GAFLP{i}L 16-bit (i=110..115)
{0xFFCFFECC+0x10*i} RSCAN0GAFLP{i}LL (i=110..115)
{0xFFCFFECD+0x10*i} RSCAN0GAFLP{i}LH (i=110..115)
{0xFFCFFECE+0x10*i} RSCAN0GAFLP{i}H 16-bit (i=110..115)
{0xFFCFFECE+0x10*i} RSCAN0GAFLP{i}HL (i=110..115)
{0xFFCFFECF+0x10*i} RSCAN0GAFLP{i}HH (i=110..115)
0xFFD005B8 RSCAN0GAFLP011 32-bit
0xFFD005B8 RSCAN0GAFLP011L 16-bit
0xFFD005B9 RSCAN0GAFLP011LH
0xFFD005BA RSCAN0GAFLP011H 16-bit
0xFFD005BA RSCAN0GAFLP011HL
0xFFD005BB RSCAN0GAFLP011HH
0xFFD005C8 RSCAN0GAFLP012 32-bit
0xFFD005C8 RSCAN0GAFLP012L 16-bit
0xFFD005C9 RSCAN0GAFLP012LH
0xFFD005CA RSCAN0GAFLP012H 16-bit
0xFFD005CA RSCAN0GAFLP012HL
0xFFD005CB RSCAN0GAFLP012HH
0xFFD005D8 RSCAN0GAFLP013 32-bit
0xFFD005D8 RSCAN0GAFLP013L 16-bit
0xFFD005D9 RSCAN0GAFLP013LH
0xFFD005DA RSCAN0GAFLP013H 16-bit
0xFFD005DA RSCAN0GAFLP013HL
0xFFD005DB RSCAN0GAFLP013HH
0xFFD005E8 RSCAN0GAFLP014 32-bit
0xFFD005E8 RSCAN0GAFLP014L 16-bit
0xFFD005E9 RSCAN0GAFLP014LH
0xFFD005EA RSCAN0GAFLP014H 16-bit
0xFFD005EA RSCAN0GAFLP014HL
0xFFD005EB RSCAN0GAFLP014HH
0xFFD005F8 RSCAN0GAFLP015 32-bit
0xFFD005F8 RSCAN0GAFLP015L 16-bit
0xFFD005F9 RSCAN0GAFLP015LH
0xFFD005FA RSCAN0GAFLP015H 16-bit
0xFFD005FA RSCAN0GAFLP015HL
0xFFD005FB RSCAN0GAFLP015HH
{0xFFD00600+0x10*i} RSCAN0RMID{i} 32-bit ro (i=0..95)
{0xFFD00600+0x10*i} RSCAN0RMID{i}L 16-bit ro (i=0..95)
{0xFFD00600+0x10*i} RSCAN0RMID{i}LL ro (i=0..95)
{0xFFD00601+0x10*i} RSCAN0RMID{i}LH ro (i=0..95)
{0xFFD00602+0x10*i} RSCAN0RMID{i}H 16-bit ro (i=0..95)
{0xFFD00602+0x10*i} RSCAN0RMID{i}HL ro (i=0..95)
{0xFFD00603+0x10*i} RSCAN0RMID{i}HH ro (i=0..95)
{0xFFD00604+0x10*i} RSCAN0RMPTR{i} 32-bit ro (i=0..95)
{0xFFD00604+0x10*i} RSCAN0RMPTR{i}L 16-bit ro (i=0..95)
{0xFFD00604+0x10*i} RSCAN0RMPTR{i}LL ro (i=0..95)
{0xFFD00605+0x10*i} RSCAN0RMPTR{i}LH ro (i=0..95)
{0xFFD00606+0x10*i} RSCAN0RMPTR{i}H 16-bit ro (i=0..95)
{0xFFD00606+0x10*i} RSCAN0RMPTR{i}HL ro (i=0..95)
{0xFFD00607+0x10*i} RSCAN0RMPTR{i}HH ro (i=0..95)
{0xFFD00608+0x10*i} RSCAN0RMDF{i:02} 32-bit ro (i=0..9)
{0xFFD00608+0x10*i} RSCAN0RMDF{i:02}L 16-bit ro (i=0..9)
{0xFFD00608+0x10*i} RSCAN0RMDF{i:02}LL ro (i=0..9)
{0xFFD00609+0x10*i} RSCAN0RMDF{i:02}LH ro (i=0..9)
{0xFFD0060A+0x10*i} RSCAN0RMDF{i:02}H 16-bit ro (i=0..9)
{0xFFD0060A+0x10*i} RSCAN0RMDF{i:02}HL ro (i=0..9)
{0xFFD0060B+0x10*i} RSCAN0RMDF{i:02}HH ro (i=0..9)
0xFFD0060C RSCAN0RMDF10 32-bit ro
0xFFD0060C RSCAN0RMDF10L 16-bit ro
0xFFD0060C RSCAN0RMDF10LL ro
0xFFD0060D RSCAN0RMDF10LH ro
0xFFD0060E RSCAN0RMDF10H 16-bit ro
0xFFD0060E RSCAN0RMDF10HL ro
0xFFD0060F RSCAN0RMDF10HH ro
0xFFD0061C RSCAN0RMDF11 32-bit ro
0xFFD0061C RSCAN0RMDF11L 16-bit ro
0xFFD0061C RSCAN0RMDF11LL ro
0xFFD0061D RSCAN0RMDF11LH ro
0xFFD0061E RSCAN0RMDF11H 16-bit ro
0xFFD0061E RSCAN0RMDF11HL ro
0xFFD0061F RSCAN0RMDF11HH ro
0xFFD0062C RSCAN0RMDF12 32-bit ro
0xFFD0062C RSCAN0RMDF12L 16-bit ro
0xFFD0062C RSCAN0RMDF12LL ro
0xFFD0062D RSCAN0RMDF12LH ro
0xFFD0062E RSCAN0RMDF12H 16-bit ro
0xFFD0062E RSCAN0RMDF12HL ro
0xFFD0062F RSCAN0RMDF12HH ro
0xFFD0063C RSCAN0RMDF13 32-bit ro
0xFFD0063C RSCAN0RMDF13L 16-bit ro
0xFFD0063C RSCAN0RMDF13LL ro
0xFFD0063D RSCAN0RMDF13LH ro
0xFFD0063E RSCAN0RMDF13H 16-bit ro
0xFFD0063E RSCAN0RMDF13HL ro
0xFFD0063F RSCAN0RMDF13HH ro
0xFFD0064C RSCAN0RMDF14 32-bit ro
0xFFD0064C RSCAN0RMDF14L 16-bit ro
0xFFD0064C RSCAN0RMDF14LL ro
0xFFD0064D RSCAN0RMDF14LH ro
0xFFD0064E RSCAN0RMDF14H 16-bit ro
0xFFD0064E RSCAN0RMDF14HL ro
0xFFD0064F RSCAN0RMDF14HH ro
0xFFD0065C RSCAN0RMDF15 32-bit ro
0xFFD0065C RSCAN0RMDF15L 16-bit ro
0xFFD0065C RSCAN0RMDF15LL ro
0xFFD0065D RSCAN0RMDF15LH ro
0xFFD0065E RSCAN0RMDF15H 16-bit ro
0xFFD0065E RSCAN0RMDF15HL ro
0xFFD0065F RSCAN0RMDF15HH ro
0xFFD0066C RSCAN0RMDF16 32-bit ro
0xFFD0066C RSCAN0RMDF16L 16-bit ro
0xFFD0066C RSCAN0RMDF16LL ro
0xFFD0066D RSCAN0RMDF16LH ro
0xFFD0066E RSCAN0RMDF16H 16-bit ro
0xFFD0066E RSCAN0RMDF16HL ro
0xFFD0066F RSCAN0RMDF16HH ro
0xFFD0067C RSCAN0RMDF17 32-bit ro
0xFFD0067C RSCAN0RMDF17L 16-bit ro
0xFFD0067C RSCAN0RMDF17LL ro
0xFFD0067D RSCAN0RMDF17LH ro
0xFFD0067E RSCAN0RMDF17H 16-bit ro
0xFFD0067E RSCAN0RMDF17HL ro
0xFFD0067F RSCAN0RMDF17HH ro
0xFFD0068C RSCAN0RMDF18 32-bit ro
0xFFD0068C RSCAN0RMDF18L 16-bit ro
0xFFD0068C RSCAN0RMDF18LL ro
0xFFD0068D RSCAN0RMDF18LH ro
0xFFD0068E RSCAN0RMDF18H 16-bit ro
0xFFD0068E RSCAN0RMDF18HL ro
0xFFD0068F RSCAN0RMDF18HH ro
0xFFD0069C RSCAN0RMDF19 32-bit ro
0xFFD0069C RSCAN0RMDF19L 16-bit ro
0xFFD0069C RSCAN0RMDF19LL ro
0xFFD0069D RSCAN0RMDF19LH ro
0xFFD0069E RSCAN0RMDF19H 16-bit ro
0xFFD0069E RSCAN0RMDF19HL ro
0xFFD0069F RSCAN0RMDF19HH ro
0xFFD006A8 RSCAN0RMDF010 32-bit ro
0xFFD006A8 RSCAN0RMDF010L 16-bit ro
0xFFD006A8 RSCAN0RMDF010LL ro
0xFFD006A9 RSCAN0RMDF010LH ro
0xFFD006AA RSCAN0RMDF010H 16-bit ro
0xFFD006AA RSCAN0RMDF010HL ro
0xFFD006AB RSCAN0RMDF010HH ro
{0xFFCFFFCC+0x10*i} RSCAN0RMDF{i} 32-bit ro (i=110..195)
{0xFFCFFFCC+0x10*i} RSCAN0RMDF{i}L 16-bit ro (i=110..195)
{0xFFCFFFCC+0x10*i} RSCAN0RMDF{i}LL ro (i=110..195)
{0xFFCFFFCD+0x10*i} RSCAN0RMDF{i}LH ro (i=110..195)
{0xFFCFFFCE+0x10*i} RSCAN0RMDF{i}H 16-bit ro (i=110..195)
{0xFFCFFFCE+0x10*i} RSCAN0RMDF{i}HL ro (i=110..195)
{0xFFCFFFCF+0x10*i} RSCAN0RMDF{i}HH ro (i=110..195)
0xFFD006B8 RSCAN0RMDF011 32-bit ro
0xFFD006B8 RSCAN0RMDF011L 16-bit ro
0xFFD006B8 RSCAN0RMDF011LL ro
0xFFD006B9 RSCAN0RMDF011LH ro
0xFFD006BA RSCAN0RMDF011H 16-bit ro
0xFFD006BA RSCAN0RMDF011HL ro
0xFFD006BB RSCAN0RMDF011HH ro
0xFFD006C8 RSCAN0RMDF012 32-bit ro
0xFFD006C8 RSCAN0RMDF012L 16-bit ro
0xFFD006C8 RSCAN0RMDF012LL ro
0xFFD006C9 RSCAN0RMDF012LH ro
0xFFD006CA RSCAN0RMDF012H 16-bit ro
0xFFD006CA RSCAN0RMDF012HL ro
0xFFD006CB RSCAN0RMDF012HH ro
0xFFD006D8 RSCAN0RMDF013 32-bit ro
0xFFD006D8 RSCAN0RMDF013L 16-bit ro
0xFFD006D8 RSCAN0RMDF013LL ro
0xFFD006D9 RSCAN0RMDF013LH ro
0xFFD006DA RSCAN0RMDF013H 16-bit ro
0xFFD006DA RSCAN0RMDF013HL ro
0xFFD006DB RSCAN0RMDF013HH ro
0xFFD006E8 RSCAN0RMDF014 32-bit ro
0xFFD006E8 RSCAN0RMDF014L 16-bit ro
0xFFD006E8 RSCAN0RMDF014LL ro
0xFFD006E9 RSCAN0RMDF014LH ro
0xFFD006EA RSCAN0RMDF014H 16-bit ro
0xFFD006EA RSCAN0RMDF014HL ro
0xFFD006EB RSCAN0RMDF014HH ro
0xFFD006F8 RSCAN0RMDF015 32-bit ro
0xFFD006F8 RSCAN0RMDF015L 16-bit ro
0xFFD006F8 RSCAN0RMDF015LL ro
0xFFD006F9 RSCAN0RMDF015LH ro
0xFFD006FA RSCAN0RMDF015H 16-bit ro
0xFFD006FA RSCAN0RMDF015HL ro
0xFFD006FB RSCAN0RMDF015HH ro
0xFFD00708 RSCAN0RMDF016 32-bit ro
0xFFD00708 RSCAN0RMDF016L 16-bit ro
0xFFD00708 RSCAN0RMDF016LL ro
0xFFD00709 RSCAN0RMDF016LH ro
0xFFD0070A RSCAN0RMDF016H 16-bit ro
0xFFD0070A RSCAN0RMDF016HL ro
0xFFD0070B RSCAN0RMDF016HH ro
0xFFD00718 RSCAN0RMDF017 32-bit ro
0xFFD00718 RSCAN0RMDF017L 16-bit ro
0xFFD00718 RSCAN0RMDF017LL ro
0xFFD00719 RSCAN0RMDF017LH ro
0xFFD0071A RSCAN0RMDF017H 16-bit ro
0xFFD0071A RSCAN0RMDF017HL ro
0xFFD0071B RSCAN0RMDF017HH ro
0xFFD00728 RSCAN0RMDF018 32-bit ro
0xFFD00728 RSCAN0RMDF018L 16-bit ro
0xFFD00728 RSCAN0RMDF018LL ro
0xFFD00729 RSCAN0RMDF018LH ro
0xFFD0072A RSCAN0RMDF018H 16-bit ro
0xFFD0072A RSCAN0RMDF018HL ro
0xFFD0072B RSCAN0RMDF018HH ro
{0xFFD00608+0x10*i} RSCAN0RMDF{i:03} 32-bit ro (i=19..95)
{0xFFD00608+0x10*i} RSCAN0RMDF{i:03}L 16-bit ro (i=19..95)
{0xFFD00608+0x10*i} RSCAN0RMDF{i:03}LL ro (i=19..95)
{0xFFD00609+0x10*i} RSCAN0RMDF{i:03}LH ro (i=19..95)
{0xFFD0060A+0x10*i} RSCAN0RMDF{i:03}H 16-bit ro (i=19..95)
{0xFFD0060A+0x10*i} RSCAN0RMDF{i:03}HL ro (i=19..95)
{0xFFD0060B+0x10*i} RSCAN0RMDF{i:03}HH ro (i=19..95)
{0xFFD00E00+0x10*i} RSCAN0RFID{i} 32-bit ro (i=0..7)
{0xFFD00E00+0x10*i} RSCAN0RFID{i}L 16-bit ro (i=0..7)
{0xFFD00E00+0x10*i} RSCAN0RFID{i}LL ro (i=0..7)
{0xFFD00E01+0x10*i} RSCAN0RFID{i}LH ro (i=0..7)
{0xFFD00E02+0x10*i} RSCAN0RFID{i}H 16-bit ro (i=0..7)
{0xFFD00E02+0x10*i} RSCAN0RFID{i}HL ro (i=0..7)
{0xFFD00E03+0x10*i} RSCAN0RFID{i}HH ro (i=0..7)
{0xFFD00E04+0x10*i} RSCAN0RFPTR{i} 32-bit ro (i=0..7)
{0xFFD00E04+0x10*i} RSCAN0RFPTR{i}L 16-bit ro (i=0..7)
{0xFFD00E04+0x10*i} RSCAN0RFPTR{i}LL ro (i=0..7)
{0xFFD00E05+0x10*i} RSCAN0RFPTR{i}LH ro (i=0..7)
{0xFFD00E06+0x10*i} RSCAN0RFPTR{i}H 16-bit ro (i=0..7)
{0xFFD00E06+0x10*i} RSCAN0RFPTR{i}HL ro (i=0..7)
{0xFFD00E07+0x10*i} RSCAN0RFPTR{i}HH ro (i=0..7)
{0xFFD00E08+0x10*i} RSCAN0RFDF{i:02} 32-bit ro (i=0..7)
{0xFFD00E08+0x10*i} RSCAN0RFDF{i:02}L 16-bit ro (i=0..7)
{0xFFD00E08+0x10*i} RSCAN0RFDF{i:02}LL ro (i=0..7)
{0xFFD00E09+0x10*i} RSCAN0RFDF{i:02}LH ro (i=0..7)
{0xFFD00E0A+0x10*i} RSCAN0RFDF{i:02}H 16-bit ro (i=0..7)
{0xFFD00E0A+0x10*i} RSCAN0RFDF{i:02}HL ro (i=0..7)
{0xFFD00E0B+0x10*i} RSCAN0RFDF{i:02}HH ro (i=0..7)
{0xFFD00D6C+0x10*i} RSCAN0RFDF{i} 32-bit ro (i=10..17)
{0xFFD00D6C+0x10*i} RSCAN0RFDF{i}L 16-bit ro (i=10..17)
{0xFFD00D6C+0x10*i} RSCAN0RFDF{i}LL ro (i=10..17)
{0xFFD00D6D+0x10*i} RSCAN0RFDF{i}LH ro (i=10..17)
{0xFFD00D6E+0x10*i} RSCAN0RFDF{i}H 16-bit ro (i=10..17)
{0xFFD00D6E+0x10*i} RSCAN0RFDF{i}HL ro (i=10..17)
{0xFFD00D6F+0x10*i} RSCAN0RFDF{i}HH ro (i=10..17)
{0xFFD00E80+0x10*i} RSCAN0CFID{i} 32-bit (i=0..17)
{0xFFD00E80+0x10*i} RSCAN0CFID{i}L 16-bit (i=0..17)
